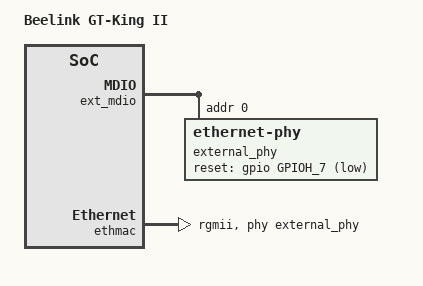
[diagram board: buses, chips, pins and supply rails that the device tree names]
#include "t7_a311d2_an400_drm_hdmitx_only.dts"
#include "coreelec_t7_common.dtsi"

/ {
	model = "Beelink GT-King II";
	coreelec-dt-id = "t7_a311d2_beelink_gt_king_ii_4g";
	amlogic-dt-id = "t7_a311d2_an400";

	memory@00000000 {
		device_type = "memory";
		linux,usable-memory = <0x00000000 0x00000000 0x00000000 0xE0000000
		                       0x00000001 0x00000000 0x00000000 0x20000000>;
	};
};

&ext_mdio {
	external_phy: ethernet-phy@0 {
		reg = <0>;
		max-speed = <1000>;

		reset-assert-us = <20000>;
		reset-deassert-us = <50000>;
		reset-gpios = <&gpio GPIOH_7 (GPIO_ACTIVE_LOW |
					GPIO_OPEN_DRAIN)>;
	};
};

&ethmac {
	pinctrl-0 = <&eth_pins>, <&eth_rgmii_pins>;
	pinctrl-names = "default";
	status = "okay";
	phy-mode = "rgmii";
	phy-handle = <&external_phy>;
	amlogic,tx-delay-ns = <2>;
};
